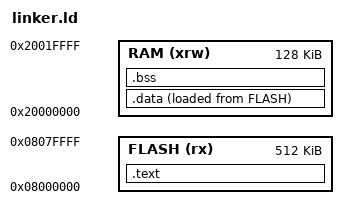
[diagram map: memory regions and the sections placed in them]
ENTRY(Reset_Handler) /* Точка входа (она описана в ассемблерном стартапе) */

/* Конец оперативной памяти 0х20000000 + 128К*/
_estack = 0x20020000;

/* Указываем точные физические адреса памяти чипа STM32f446RE */
MEMORY
{
    FLASH (rx)          : ORIGIN = 0x08000000, LENGTH = 512K
    RAM (xrw)           : ORIGIN = 0x20000000, LENGTH = 128K
}


/* Распределяем разделы кода по полочкам памяти */
SECTIONS
{
    /* Весь исполняемый код и стартап идут во FLASH память */
    .text :
    {
        KEEP(*(.isr_vector)) /* Вектора прерываний - строго в самом начале! */
        *(.text)        /* Сам наш Си-код */
        *(.rodata)      /* Константы */
        _etext = .;
    } > FLASH


    /* Переменные стартапа, которые инициализируют память */

    _sidata = LOADADDR(.data);

    /* Переменные идут в оперативную память RAM */
    .data :
    {
        _sdata = .;
        *(.data*)
        _edata = .;
    } > RAM AT > FLASH

    .bss :
    {
        _sbss = .;
        __bss_start__ = _sbss; /* Для совместимости с libc */
        *(.bss*)
        _ebss = .;
        __bss_end__ = _ebss; /* Для совместимости с libc */
    } > RAM
}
